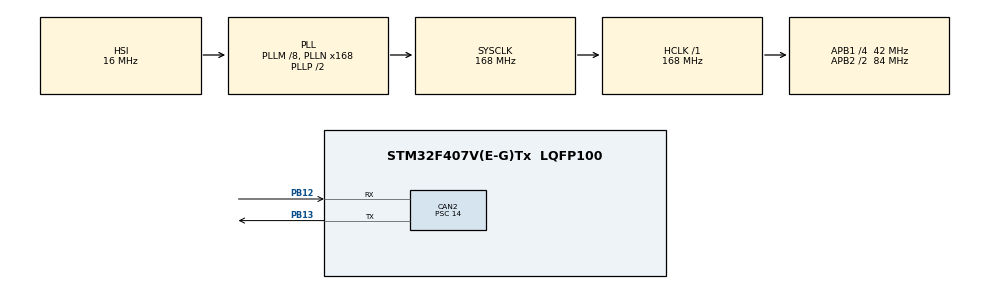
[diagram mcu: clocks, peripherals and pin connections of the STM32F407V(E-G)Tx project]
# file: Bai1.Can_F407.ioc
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CAN2.ABOM=DISABLE
CAN2.BS1=CAN_BS1_2TQ
CAN2.BS2=CAN_BS2_3TQ
CAN2.CalculateBaudRate=499999
CAN2.CalculateTimeBit=2000
CAN2.CalculateTimeQuantum=333.33333333333337
CAN2.NART=ENABLE
CAN2.Prescaler=14
CAN2.SJW=CAN_SJW_2TQ
CAN2.TTCM=DISABLE
CAN2.TXFP=DISABLE
Mcu.Family=STM32F4
Mcu.Name=STM32F407V(E-G)Tx
Mcu.Package=LQFP100
NVIC.CAN2_RX0_IRQn=true\:0\:0\:false\:false\:true\:true\:true\:true
NVIC.PriorityGroup=NVIC_PRIORITYGROUP_4
PA13.Mode=Serial_Wire
PA13.Signal=SYS_JTMS-SWDIO
PA14.Mode=Serial_Wire
PA14.Signal=SYS_JTCK-SWCLK
PB12.Mode=CAN_Activate
PB12.Signal=CAN2_RX
PB13.Mode=CAN_Activate
PB13.Signal=CAN2_TX
PH0-OSC_IN.Mode=HSE-External-Oscillator
PH0-OSC_IN.Signal=RCC_OSC_IN
PH1-OSC_OUT.Mode=HSE-External-Oscillator
PH1-OSC_OUT.Signal=RCC_OSC_OUT
ProjectManager.HeapSize=0x200
ProjectManager.StackSize=0x400
ProjectManager.TargetToolchain=MDK-ARM V5.32
RCC.48MHZClocksFreq_Value=84000000
RCC.AHBFreq_Value=168000000
RCC.APB1CLKDivider=RCC_HCLK_DIV4
RCC.APB1Freq_Value=42000000
RCC.APB1TimFreq_Value=84000000
RCC.APB2CLKDivider=RCC_HCLK_DIV2
RCC.APB2Freq_Value=84000000
RCC.APB2TimFreq_Value=168000000
RCC.CortexFreq_Value=168000000
RCC.HCLKFreq_Value=168000000
RCC.HSE_VALUE=25000000
RCC.HSI_VALUE=16000000
RCC.LSE_VALUE=32768
RCC.PLLM=8
RCC.PLLN=168
RCC.SYSCLKFreq_VALUE=168000000
RCC.SYSCLKSource=RCC_SYSCLKSOURCE_PLLCLK
RCC.VCOOutputFreq_Value=336000000
board=custom

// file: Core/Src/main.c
/* USER CODE BEGIN Header */
/**
  ******************************************************************************
  * @file           : main.c
  * @brief          : Main program body
  ******************************************************************************
  * @attention
  *
  * Copyright (c) 2023 STMicroelectronics.
  * All rights reserved.
  *
  * This software is licensed under terms that can be found in the LICENSE file
  * in the root directory of this software component.
  * If no LICENSE file comes with this software, it is provided AS-IS.
  *
  ******************************************************************************
  */
/* USER CODE END Header */
#include "main.h"

/* USER CODE BEGIN Includes */
#include "string.h"
/* USER CODE END Includes */

CAN_HandleTypeDef hcan2;

/* USER CODE BEGIN PV */
int16_t failsafe = 0;

CAN_HandleTypeDef     CanHandle;
CAN_TxHeaderTypeDef   TxHeader;
CAN_RxHeaderTypeDef   RxHeader;
uint8_t               TxData[8];
uint8_t               RxData[8];
uint32_t              TxMailbox;

int F103Data = 0;
int F750Data = 0;

int indx = 0;
/* USER CODE END PV */

void SystemClock_Config(void);
static void MX_GPIO_Init(void);
static void MX_CAN2_Init(void);

/* USER CODE BEGIN 0 */
void HAL_CAN_RxFifo0MsgPendingCallback(CAN_HandleTypeDef *hcan)
{
  if (HAL_CAN_GetRxMessage(hcan, CAN_RX_FIFO0, &RxHeader, RxData) != HAL_OK)
  {
    Error_Handler();
  }

  // additional filter
  if (RxHeader.StdId == 0x211) /* F103 ID */
  {
	  F103Data = 1;
	  F750Data = 0;
  }

  else if (RxHeader.StdId == 0x215) /* F750 ID */
  {
	  F750Data = 1;
	  F103Data = 0;
  }

  failsafe = 3000;
}
/* USER CODE END 0 */

int main(void)
{

  /* MCU Configuration--------------------------------------------------------*/

  /* Reset of all peripherals, Initializes the Flash interface and the Systick. */
  HAL_Init();

  /* Configure the system clock */
  SystemClock_Config();

  /* Initialize all configured peripherals */
  MX_GPIO_Init();
  MX_CAN2_Init();
  /* USER CODE BEGIN 2 */

  if (HAL_CAN_Start(&hcan2) != HAL_OK)
  {
	  Error_Handler();
  }

  if (HAL_CAN_ActivateNotification(&hcan2, CAN_IT_RX_FIFO0_MSG_PENDING) != HAL_OK)
  {
	  Error_Handler();
  }

	TxHeader.StdId = 0x446;
	TxHeader.ExtId = 0x00;
	TxHeader.RTR = CAN_RTR_DATA;
	TxHeader.IDE = CAN_ID_STD;
	TxHeader.DLC = 4;
	TxHeader.TransmitGlobalTime = DISABLE;

	HAL_Delay (1000);

	strcpy ((char *)TxData, "F103");
	HAL_CAN_AddTxMessage(&hcan2, &TxHeader, TxData, &TxMailbox);
  /* USER CODE END 2 */

  /* Infinite loop */
  while (1)
  {

    /* USER CODE BEGIN 3 */
		HAL_CAN_AddTxMessage(&hcan2, &TxHeader, TxData, &TxMailbox);
		HAL_Delay(10000);
		indx++;
//		  if (F103Data || F750Data)
//	  {

//		  if (F103Data)	strcpy((char *)TxData, "F750");
//		  else if (F750Data) strcpy ((char *)TxData, "F103");

//		  F103Data = F750Data = 0;

//		  HAL_Delay(500);

//	  	HAL_CAN_AddTxMessage(&hcan2, &TxHeader, TxData, &TxMailbox);
//
//			failsafe = 100;
//	  }
  }
  /* USER CODE END 3 */
}

void SystemClock_Config(void)
{
  RCC_OscInitTypeDef RCC_OscInitStruct = {0};
  RCC_ClkInitTypeDef RCC_ClkInitStruct = {0};

  /** Configure the main internal regulator output voltage
  */
  __HAL_RCC_PWR_CLK_ENABLE();
  __HAL_PWR_VOLTAGESCALING_CONFIG(PWR_REGULATOR_VOLTAGE_SCALE1);

  /** Initializes the RCC Oscillators according to the specified parameters
  * in the RCC_OscInitTypeDef structure.
  */
  RCC_OscInitStruct.OscillatorType = RCC_OSCILLATORTYPE_HSI;
  RCC_OscInitStruct.HSIState = RCC_HSI_ON;
  RCC_OscInitStruct.HSICalibrationValue = RCC_HSICALIBRATION_DEFAULT;
  RCC_OscInitStruct.PLL.PLLState = RCC_PLL_ON;
  RCC_OscInitStruct.PLL.PLLSource = RCC_PLLSOURCE_HSI;
  RCC_OscInitStruct.PLL.PLLM = 8;
  RCC_OscInitStruct.PLL.PLLN = 168;
  RCC_OscInitStruct.PLL.PLLP = RCC_PLLP_DIV2;
  RCC_OscInitStruct.PLL.PLLQ = 4;
  if (HAL_RCC_OscConfig(&RCC_OscInitStruct) != HAL_OK)
  {
    Error_Handler();
  }

  /** Initializes the CPU, AHB and APB buses clocks
  */
  RCC_ClkInitStruct.ClockType = RCC_CLOCKTYPE_HCLK|RCC_CLOCKTYPE_SYSCLK
                              |RCC_CLOCKTYPE_PCLK1|RCC_CLOCKTYPE_PCLK2;
  RCC_ClkInitStruct.SYSCLKSource = RCC_SYSCLKSOURCE_PLLCLK;
  RCC_ClkInitStruct.AHBCLKDivider = RCC_SYSCLK_DIV1;
  RCC_ClkInitStruct.APB1CLKDivider = RCC_HCLK_DIV4;
  RCC_ClkInitStruct.APB2CLKDivider = RCC_HCLK_DIV2;

  if (HAL_RCC_ClockConfig(&RCC_ClkInitStruct, FLASH_LATENCY_5) != HAL_OK)
  {
    Error_Handler();
  }
}

static void MX_CAN2_Init(void)
{

  hcan2.Instance = CAN2;
  hcan2.Init.Prescaler = 14;
  hcan2.Init.Mode = CAN_MODE_NORMAL;
  hcan2.Init.SyncJumpWidth = CAN_SJW_2TQ;
  hcan2.Init.TimeSeg1 = CAN_BS1_2TQ;
  hcan2.Init.TimeSeg2 = CAN_BS2_3TQ;
  hcan2.Init.TimeTriggeredMode = DISABLE;
  hcan2.Init.AutoBusOff = DISABLE;
  hcan2.Init.AutoWakeUp = DISABLE;
  hcan2.Init.AutoRetransmission = ENABLE;
  hcan2.Init.ReceiveFifoLocked = DISABLE;
  hcan2.Init.TransmitFifoPriority = DISABLE;
  if (HAL_CAN_Init(&hcan2) != HAL_OK)
  {
    Error_Handler();
  }
  /* USER CODE BEGIN CAN2_Init 2 */

	CAN_FilterTypeDef canfilterconfig;

  canfilterconfig.FilterActivation = CAN_FILTER_ENABLE;
  canfilterconfig.FilterBank = 18;  // which filter bank to use from the assigned ones
  canfilterconfig.FilterFIFOAssignment = CAN_FILTER_FIFO0;
  canfilterconfig.FilterIdHigh = 0x201<<5;
  canfilterconfig.FilterIdLow = 0;
  canfilterconfig.FilterMaskIdHigh = 0x201<<5;
  canfilterconfig.FilterMaskIdLow = 0x0000;
  canfilterconfig.FilterMode = CAN_FILTERMODE_IDMASK;
  canfilterconfig.FilterScale = CAN_FILTERSCALE_32BIT;
  canfilterconfig.SlaveStartFilterBank = 40;  // how many filters to assign to the CAN1 (master can)

  HAL_CAN_ConfigFilter(&hcan2, &canfilterconfig);
  /* USER CODE END CAN2_Init 2 */

}

static void MX_GPIO_Init(void)
{

  /* GPIO Ports Clock Enable */
  __HAL_RCC_GPIOH_CLK_ENABLE();
  __HAL_RCC_GPIOB_CLK_ENABLE();
  __HAL_RCC_GPIOA_CLK_ENABLE();

}

void Error_Handler(void)
{
  __disable_irq();
  while (1)
  {
  }
}
